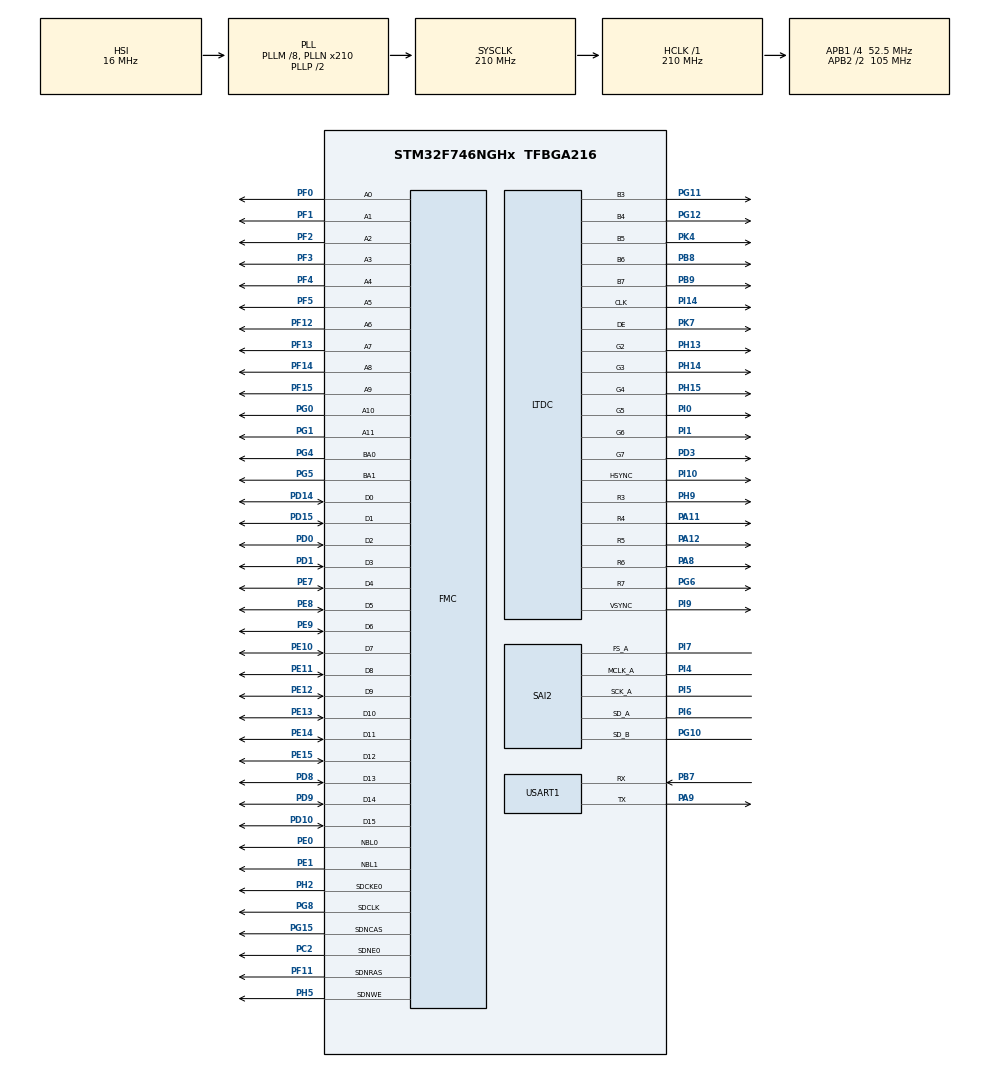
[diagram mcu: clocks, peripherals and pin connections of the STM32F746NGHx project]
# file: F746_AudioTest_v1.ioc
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Dma.Request0=SAI2_A
Dma.Request1=SAI2_B
Dma.SAI2_A.0.Direction=DMA_MEMORY_TO_PERIPH
Dma.SAI2_A.0.FIFOMode=DMA_FIFOMODE_DISABLE
Dma.SAI2_A.0.Instance=DMA2_Stream4
Dma.SAI2_A.0.MemDataAlignment=DMA_MDATAALIGN_HALFWORD
Dma.SAI2_A.0.MemInc=DMA_MINC_ENABLE
Dma.SAI2_A.0.Mode=DMA_CIRCULAR
Dma.SAI2_A.0.PeriphDataAlignment=DMA_PDATAALIGN_HALFWORD
Dma.SAI2_A.0.PeriphInc=DMA_PINC_DISABLE
Dma.SAI2_A.0.Priority=DMA_PRIORITY_HIGH
Dma.SAI2_B.1.Direction=DMA_PERIPH_TO_MEMORY
Dma.SAI2_B.1.FIFOMode=DMA_FIFOMODE_DISABLE
Dma.SAI2_B.1.Instance=DMA2_Stream6
Dma.SAI2_B.1.MemDataAlignment=DMA_MDATAALIGN_HALFWORD
Dma.SAI2_B.1.MemInc=DMA_MINC_ENABLE
Dma.SAI2_B.1.Mode=DMA_CIRCULAR
Dma.SAI2_B.1.PeriphDataAlignment=DMA_PDATAALIGN_HALFWORD
Dma.SAI2_B.1.PeriphInc=DMA_PINC_DISABLE
Dma.SAI2_B.1.Priority=DMA_PRIORITY_HIGH
Mcu.Family=STM32F7
Mcu.Name=STM32F746NGHx
Mcu.Package=TFBGA216
NVIC.DMA2D_IRQn=true\:0\:0\:false\:false\:true\:true\:true\:true
NVIC.DMA2_Stream4_IRQn=true\:0\:0\:false\:false\:true\:false\:true\:true
NVIC.DMA2_Stream6_IRQn=true\:0\:0\:false\:false\:true\:false\:true\:true
NVIC.LTDC_IRQn=true\:0\:0\:false\:false\:true\:true\:true\:true
NVIC.PriorityGroup=NVIC_PRIORITYGROUP_4
PA11.Mode=RGB565
PA11.Signal=LTDC_R4
PA12.Mode=RGB565
PA12.Signal=LTDC_R5
PA13.Mode=Serial_Wire
PA13.Signal=SYS_JTMS-SWDIO
PA14.Mode=Serial_Wire
PA14.Signal=SYS_JTCK-SWCLK
PA8.Mode=RGB565
PA8.Signal=LTDC_R6
PA9.Mode=Asynchronous
PA9.Signal=USART1_TX
PB7.Mode=Asynchronous
PB7.Signal=USART1_RX
PB8.Mode=RGB565
PB8.Signal=LTDC_B6
PB9.Mode=RGB565
PB9.Signal=LTDC_B7
PC14/OSC32_IN.Mode=LSE-External-Oscillator
PC14/OSC32_IN.Signal=RCC_OSC32_IN
PC15/OSC32_OUT.Mode=LSE-External-Oscillator
PC15/OSC32_OUT.Signal=RCC_OSC32_OUT
PC2.Mode=SdramChipSelect1_1
PC2.Signal=FMC_SDNE0
PD0.Signal=FMC_D2_DA2
PD1.Signal=FMC_D3_DA3
PD10.Signal=FMC_D15_DA15
PD14.Signal=FMC_D0_DA0
PD15.Signal=FMC_D1_DA1
PD3.Mode=RGB565
PD3.Signal=LTDC_G7
PD8.Signal=FMC_D13_DA13
PD9.Signal=FMC_D14_DA14
PE0.Signal=FMC_NBL0
PE1.Signal=FMC_NBL1
PE10.Signal=FMC_D7_DA7
PE11.Signal=FMC_D8_DA8
PE12.Signal=FMC_D9_DA9
PE13.Signal=FMC_D10_DA10
PE14.Signal=FMC_D11_DA11
PE15.Signal=FMC_D12_DA12
PE7.Signal=FMC_D4_DA4
PE8.Signal=FMC_D5_DA5
PE9.Signal=FMC_D6_DA6
PF0.Signal=FMC_A0
PF1.Signal=FMC_A1
PF11.Signal=FMC_SDNRAS
PF12.Signal=FMC_A6
PF13.Signal=FMC_A7
PF14.Signal=FMC_A8
PF15.Signal=FMC_A9
PF2.Signal=FMC_A2
PF3.Signal=FMC_A3
PF4.Signal=FMC_A4
PF5.Signal=FMC_A5
PG0.Signal=FMC_A10
PG1.Signal=FMC_A11
PG10.Mode=SAI_B_SyncSlave
PG10.Signal=SAI2_SD_B
PG11.Mode=RGB565
PG11.Signal=LTDC_B3
PG12.Mode=RGB565
PG12.Signal=LTDC_B4
PG15.Signal=FMC_SDNCAS
PG4.Signal=FMC_A14_BA0
PG5.Signal=FMC_A15_BA1
PG6.Mode=RGB565
PG6.Signal=LTDC_R7
PG8.Signal=FMC_SDCLK
PH0/OSC_IN.Mode=HSE-External-Oscillator
PH0/OSC_IN.Signal=RCC_OSC_IN
PH1/OSC_OUT.Mode=HSE-External-Oscillator
PH1/OSC_OUT.Signal=RCC_OSC_OUT
PH13.Mode=RGB565
PH13.Signal=LTDC_G2
PH14.Mode=RGB565
PH14.Signal=LTDC_G3
PH15.Mode=RGB565
PH15.Signal=LTDC_G4
PH2.Mode=SdramChipSelect1_1
PH2.Signal=FMC_SDCKE0
PH5.Signal=FMC_SDNWE
PH9.Mode=RGB565
PH9.Signal=LTDC_R3
PI0.Mode=RGB565
PI0.Signal=LTDC_G5
PI1.Mode=RGB565
PI1.Signal=LTDC_G6
PI10.Mode=RGB565
PI10.Signal=LTDC_HSYNC
PI14.Mode=RGB565
PI14.Signal=LTDC_CLK
PI4.Mode=SAI_A_MasterWithClock
PI4.Signal=SAI2_MCLK_A
PI5.Mode=SAI_A_MasterWithClock
PI5.Signal=SAI2_SCK_A
PI6.Mode=SAI_A_MasterWithClock
PI6.Signal=SAI2_SD_A
PI7.Mode=SAI_A_MasterWithClock
PI7.Signal=SAI2_FS_A
PI9.Mode=RGB565
PI9.Signal=LTDC_VSYNC
PK4.Mode=RGB565
PK4.Signal=LTDC_B5
PK7.Mode=RGB565
PK7.Signal=LTDC_DE
ProjectManager.HeapSize=0x200
ProjectManager.StackSize=0x400
ProjectManager.TargetToolchain=CMake
RCC.AHBFreq_Value=210000000
RCC.APB1CLKDivider=RCC_HCLK_DIV4
RCC.APB1Freq_Value=52500000
RCC.APB1TimFreq_Value=105000000
RCC.APB2CLKDivider=RCC_HCLK_DIV2
RCC.APB2Freq_Value=105000000
RCC.APB2TimFreq_Value=210000000
RCC.CortexFreq_Value=210000000
RCC.HCLKFreq_Value=210000000
RCC.HSE_VALUE=25000000
RCC.HSI_VALUE=16000000
RCC.PLLM=8
RCC.PLLN=210
RCC.PLLSAIN=50
RCC.PLLSourceVirtual=RCC_PLLSOURCE_HSI
RCC.SYSCLKFreq_VALUE=210000000
RCC.SYSCLKSource=RCC_SYSCLKSOURCE_PLLCLK
RCC.USBFreq_Value=210000000
RCC.VCOOutputFreq_Value=420000000
SAI2.ErrorAudioFreq-SAI_A_MasterWithClock=56.25 %
SAI2.Instance-SAI_A_MasterWithClock=SAI$Index_Block_A
SAI2.Instance-SAI_B_SyncSlave=SAI$Index_Block_B
SAI2.MClockEnable-SAI_A_MasterWithClock=SAI_MASTERCLOCK_ENABLE
SAI2.RealAudioFreq-SAI_A_MasterWithClock=300.0 KHz
SAI2.VirtualMode-SAI_A_MasterWithClock=VM_MASTER
SAI2.VirtualMode-SAI_B_SyncSlave=VM_SLAVE
SH.FMC_A0.0=FMC_A0,12b-sda1
SH.FMC_A1.0=FMC_A1,12b-sda1
SH.FMC_A10.0=FMC_A10,12b-sda1
SH.FMC_A11.0=FMC_A11,12b-sda1
SH.FMC_A14_BA0.0=FMC_BA0,FourSdramBanks1
SH.FMC_A15_BA1.0=FMC_BA1,FourSdramBanks1
SH.FMC_A2.0=FMC_A2,12b-sda1
SH.FMC_A3.0=FMC_A3,12b-sda1
SH.FMC_A4.0=FMC_A4,12b-sda1
SH.FMC_A5.0=FMC_A5,12b-sda1
SH.FMC_A6.0=FMC_A6,12b-sda1
SH.FMC_A7.0=FMC_A7,12b-sda1
SH.FMC_A8.0=FMC_A8,12b-sda1
SH.FMC_A9.0=FMC_A9,12b-sda1
SH.FMC_D0_DA0.0=FMC_D0,sd-16b-d1
SH.FMC_D10_DA10.0=FMC_D10,sd-16b-d1
SH.FMC_D11_DA11.0=FMC_D11,sd-16b-d1
SH.FMC_D12_DA12.0=FMC_D12,sd-16b-d1
SH.FMC_D13_DA13.0=FMC_D13,sd-16b-d1
SH.FMC_D14_DA14.0=FMC_D14,sd-16b-d1
SH.FMC_D15_DA15.0=FMC_D15,sd-16b-d1
SH.FMC_D1_DA1.0=FMC_D1,sd-16b-d1
SH.FMC_D2_DA2.0=FMC_D2,sd-16b-d1
SH.FMC_D3_DA3.0=FMC_D3,sd-16b-d1
SH.FMC_D4_DA4.0=FMC_D4,sd-16b-d1
SH.FMC_D5_DA5.0=FMC_D5,sd-16b-d1
SH.FMC_D6_DA6.0=FMC_D6,sd-16b-d1
SH.FMC_D7_DA7.0=FMC_D7,sd-16b-d1
SH.FMC_D8_DA8.0=FMC_D8,sd-16b-d1
SH.FMC_D9_DA9.0=FMC_D9,sd-16b-d1
SH.FMC_NBL0.0=FMC_NBL0,Sd2ByteEnable1
SH.FMC_NBL1.0=FMC_NBL1,Sd2ByteEnable1
SH.FMC_SDCLK.0=FMC_SDCLK,12b-sda1
SH.FMC_SDNCAS.0=FMC_SDNCAS,12b-sda1
SH.FMC_SDNRAS.0=FMC_SDNRAS,12b-sda1
SH.FMC_SDNWE.0=FMC_SDNWE,12b-sda1
USART1.VirtualMode-Asynchronous=VM_ASYNC
VP_DMA2D_VS_DMA2D.Mode=DMA2D_Activate
VP_TIM1_VS_ClockSourceINT.Mode=Internal
board=STM32F746G-DISCO

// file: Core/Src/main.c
/* USER CODE BEGIN Header */
/**
 ******************************************************************************
 * @file           : main.c
 * @brief          : Main program body
 ******************************************************************************
 * @attention
 *
 * Copyright (c) 2024 STMicroelectronics.
 * All rights reserved.
 *
 * This software is licensed under terms that can be found in the LICENSE file
 * in the root directory of this software component.
 * If no LICENSE file comes with this software, it is provided AS-IS.
 *
 ******************************************************************************
 */
/* USER CODE END Header */
#include "main.h"
#include "dma.h"
#include "dma2d.h"
#include "ltdc.h"
#include "sai.h"
#include "tim.h"
#include "usart.h"
#include "gpio.h"
#include "fmc.h"

/* USER CODE BEGIN Includes */
#include <stdio.h>
#include "stm32746g_discovery.h"
#include "stm32746g_discovery_audio.h"
#include "stm32746g_discovery_lcd.h"
#include "stm32746g_discovery_sdram.h"
#include "distortion.h"
#include "delay.h"
#include "wahwah.h"
/* USER CODE END Includes */

/* USER CODE BEGIN PTD */
typedef enum
{
  BUFFER_OFFSET_NONE = 0,
  BUFFER_OFFSET_HALF,
  BUFFER_OFFSET_FULL,
} BUFFER_StateTypeDef;
/* USER CODE END PTD */

/* USER CODE BEGIN PV */
extern SAI_HandleTypeDef haudio_out_sai;
extern SAI_HandleTypeDef haudio_in_sai;
static int16_t sampleBuffer[BUFFER_SIZE_SAMPLES];
static uint8_t saiDMATransmitBuffer[DMA_BUFFER_SIZE_BYTES];
static uint8_t saiDMAReceiveBuffer[DMA_BUFFER_SIZE_BYTES];
volatile uint32_t audio_rec_buffer_state;

// LCD Fonts
extern sFONT Font24;
extern sFONT Font20;
extern sFONT Font16;
extern sFONT Font12;
extern sFONT Font8;
/* USER CODE END PV */

void SystemClock_Config(void);
void PeriphCommonClock_Config(void);
/* USER CODE BEGIN PFP */
void PrintDMABuffer(uint8_t *buffer, size_t size);
void PrintSampleBuffer(int16_t *buffer, size_t size);
void BSP_Bringup(void);
static void AudioInit(void);
static void FillSquareWave(int16_t *buf, uint32_t num_samples);
static void ConvertSampleToDMA(int16_t *sampleBuffer, uint8_t *dmaBuffer, uint32_t num_samples);
static void ExtractSampleFromDMA(uint8_t *dmaBuffer, int16_t *sampleBuffer, uint32_t num_samples);
static void CopySampleBuffer(int16_t *dest, int16_t *orig, uint32_t num_samples);
static void CopyDMABuffer(uint8_t *dest, uint8_t *orig, uint32_t num_samples);
/* USER CODE END PFP */

/* USER CODE BEGIN 0 */
PUTCHAR_PROTOTYPE
{
  HAL_UART_Transmit(&huart1, (uint8_t *)&ch, 1, 0xFFFF);
  return ch;
}
/* USER CODE END 0 */

int main(void)
{

  /* MCU Configuration--------------------------------------------------------*/

  /* Reset of all peripherals, Initializes the Flash interface and the Systick. */
  HAL_Init();

  /* Configure the system clock */
  SystemClock_Config();

  /* Configure the peripherals common clocks */
  PeriphCommonClock_Config();

  /* Initialize all configured peripherals */
  MX_GPIO_Init();
  MX_DMA_Init();
  MX_SAI2_Init();
  MX_TIM1_Init();
  MX_USART1_UART_Init();
  MX_DMA2D_Init();
  MX_FMC_Init();
  MX_LTDC_Init();
  /* USER CODE BEGIN 2 */
  // BSP LCD Initialization
  BSP_LCD_Init();
  BSP_LCD_LayerDefaultInit(0, LCD_FB_START_ADDRESS);
  BSP_LCD_DisplayOn();
  // Layer 0
  BSP_LCD_SelectLayer(0);
  BSP_LCD_Clear(LCD_COLOR_BLACK);
  BSP_LCD_SetBackColor(LCD_COLOR_BLACK);
  BSP_LCD_SetTextColor(LCD_COLOR_WHITE);
  // Start
  BSP_LCD_SelectLayer(0);
  BSP_LCD_SetFont(&Font20);
  BSP_LCD_DisplayStringAt(0, 10, (uint8_t *)"Electric Guitar Effect Pedal", CENTER_MODE);

  // Audio Setup
  AudioInit();
  audio_rec_buffer_state = BUFFER_OFFSET_NONE;

  // Effect Setup
  WahWah_Init();
  /* USER CODE END 2 */

  /* Infinite loop */
  /* USER CODE BEGIN WHILE */
  while (1)
  {
    if (audio_rec_buffer_state != BUFFER_OFFSET_NONE)
    {
      if (audio_rec_buffer_state == BUFFER_OFFSET_HALF)
      {
        // PrintDMABuffer(&saiDMAReceiveBuffer[0], 20);
        // DistortionProcess(&saiDMAReceiveBuffer[0], 1, 600, DMA_BUFFER_SIZE_BYTES / 2);
        // DelayProcess(&saiDMAReceiveBuffer[0], 0.7, 5000, DMA_BUFFER_SIZE_BYTES / 2);
        WahWahProcess(&saiDMAReceiveBuffer[0], 250, 3, 0.3, DMA_BUFFER_SIZE_BYTES / 2);
        CopyDMABuffer(&saiDMATransmitBuffer[0], &saiDMAReceiveBuffer[0], DMA_BUFFER_SIZE_BYTES / 2);
        // ExtractSampleFromDMA(&saiDMAReceiveBuffer[0], &sampleBuffer[0], BUFFER_SIZE_SAMPLES / 2);
        // ConvertSampleToDMA(&sampleBuffer[0], &saiDMATransmitBuffer[0], BUFFER_SIZE_SAMPLES / 2);
      }
      else if (audio_rec_buffer_state == BUFFER_OFFSET_FULL)
      {
        // PrintDMABuffer(&saiDMAReceiveBuffer[DMA_BUFFER_SIZE_BYTES / 2], 20);
        // DistortionProcess(&saiDMAReceiveBuffer[DMA_BUFFER_SIZE_BYTES / 2], 1, 600, DMA_BUFFER_SIZE_BYTES / 2);
        // DelayProcess(&saiDMAReceiveBuffer[DMA_BUFFER_SIZE_BYTES / 2], 0.7, 5000, DMA_BUFFER_SIZE_BYTES / 2);
        WahWahProcess(&saiDMAReceiveBuffer[DMA_BUFFER_SIZE_BYTES / 2], 250, 3, 0.3, DMA_BUFFER_SIZE_BYTES / 2);
        CopyDMABuffer(&saiDMATransmitBuffer[DMA_BUFFER_SIZE_BYTES / 2], &saiDMAReceiveBuffer[DMA_BUFFER_SIZE_BYTES / 2], DMA_BUFFER_SIZE_BYTES / 2);
        // ExtractSampleFromDMA(&saiDMAReceiveBuffer[DMA_BUFFER_SIZE_BYTES / 2], &sampleBuffer[DMA_BUFFER_SIZE_BYTES / 2], BUFFER_SIZE_SAMPLES / 2);
        // ConvertSampleToDMA(&sampleBuffer[DMA_BUFFER_SIZE_BYTES / 2], &saiDMATransmitBuffer[DMA_BUFFER_SIZE_BYTES / 2], BUFFER_SIZE_SAMPLES / 2);
      }
      audio_rec_buffer_state = BUFFER_OFFSET_NONE;
    }
    /* USER CODE END WHILE */

  }
}

void SystemClock_Config(void)
{
  RCC_OscInitTypeDef RCC_OscInitStruct = {0};
  RCC_ClkInitTypeDef RCC_ClkInitStruct = {0};

  /** Configure LSE Drive Capability
   */
  HAL_PWR_EnableBkUpAccess();

  /** Configure the main internal regulator output voltage
   */
  __HAL_RCC_PWR_CLK_ENABLE();
  __HAL_PWR_VOLTAGESCALING_CONFIG(PWR_REGULATOR_VOLTAGE_SCALE1);

  /** Initializes the RCC Oscillators according to the specified parameters
   * in the RCC_OscInitTypeDef structure.
   */
  RCC_OscInitStruct.OscillatorType = RCC_OSCILLATORTYPE_HSI;
  RCC_OscInitStruct.HSIState = RCC_HSI_ON;
  RCC_OscInitStruct.HSICalibrationValue = RCC_HSICALIBRATION_DEFAULT;
  RCC_OscInitStruct.PLL.PLLState = RCC_PLL_ON;
  RCC_OscInitStruct.PLL.PLLSource = RCC_PLLSOURCE_HSI;
  RCC_OscInitStruct.PLL.PLLM = 8;
  RCC_OscInitStruct.PLL.PLLN = 210;
  RCC_OscInitStruct.PLL.PLLP = RCC_PLLP_DIV2;
  RCC_OscInitStruct.PLL.PLLQ = 2;
  if (HAL_RCC_OscConfig(&RCC_OscInitStruct) != HAL_OK)
  {
    Error_Handler();
  }

  /** Activate the Over-Drive mode
   */
  if (HAL_PWREx_EnableOverDrive() != HAL_OK)
  {
    Error_Handler();
  }

  /** Initializes the CPU, AHB and APB buses clocks
   */
  RCC_ClkInitStruct.ClockType = RCC_CLOCKTYPE_HCLK | RCC_CLOCKTYPE_SYSCLK | RCC_CLOCKTYPE_PCLK1 | RCC_CLOCKTYPE_PCLK2;
  RCC_ClkInitStruct.SYSCLKSource = RCC_SYSCLKSOURCE_PLLCLK;
  RCC_ClkInitStruct.AHBCLKDivider = RCC_SYSCLK_DIV1;
  RCC_ClkInitStruct.APB1CLKDivider = RCC_HCLK_DIV4;
  RCC_ClkInitStruct.APB2CLKDivider = RCC_HCLK_DIV2;

  if (HAL_RCC_ClockConfig(&RCC_ClkInitStruct, FLASH_LATENCY_6) != HAL_OK)
  {
    Error_Handler();
  }
}

void PeriphCommonClock_Config(void)
{
  RCC_PeriphCLKInitTypeDef PeriphClkInitStruct = {0};

  /** Initializes the peripherals clock
   */
  PeriphClkInitStruct.PeriphClockSelection = RCC_PERIPHCLK_LTDC | RCC_PERIPHCLK_SAI2;
  PeriphClkInitStruct.PLLSAI.PLLSAIN = 50;
  PeriphClkInitStruct.PLLSAI.PLLSAIR = 2;
  PeriphClkInitStruct.PLLSAI.PLLSAIQ = 2;
  PeriphClkInitStruct.PLLSAI.PLLSAIP = RCC_PLLSAIP_DIV2;
  PeriphClkInitStruct.PLLSAIDivQ = 1;
  PeriphClkInitStruct.PLLSAIDivR = RCC_PLLSAIDIVR_2;
  PeriphClkInitStruct.Sai2ClockSelection = RCC_SAI2CLKSOURCE_PLLSAI;
  if (HAL_RCCEx_PeriphCLKConfig(&PeriphClkInitStruct) != HAL_OK)
  {
    Error_Handler();
  }
}

/* USER CODE BEGIN 4 */
void PrintDMABuffer(uint8_t *buffer, size_t size)
{
  for (size_t i = 0; i < size; i++)
  {
    printf("%u ", buffer[i]);
  }
  printf("\n");
}

void PrintSampleBuffer(int16_t *buffer, size_t size)
{
  for (size_t i = 0; i < size; i++)
  {
    printf("%i ", buffer[i]);
  }
  printf("\n");
}

void BSP_Bringup(void)
{
  FillSquareWave(sampleBuffer, BUFFER_SIZE_SAMPLES);
  ConvertSampleToDMA(sampleBuffer, saiDMATransmitBuffer, BUFFER_SIZE_SAMPLES);
  BSP_AUDIO_OUT_Init(OUTPUT_DEVICE_HEADPHONE, VOLUME, AUDIO_FREQ);
  HAL_SAI_Transmit_DMA(&haudio_out_sai, saiDMATransmitBuffer, DMA_BUFFER_SIZE_MSIZE);

  while (1)
    ;
}

static void AudioInit(void)
{
  BSP_AUDIO_OUT_ClockConfig(&haudio_in_sai, AUDIO_FREQ, NULL);
  BSP_AUDIO_OUT_MspInit(&haudio_out_sai, NULL);
  SAIx_Out_Init(AUDIO_FREQ);
  BSP_AUDIO_IN_MspInit(&haudio_in_sai, NULL);
  SAIx_In_Init(SAI_MODESLAVE_RX, 0xF, AUDIO_FREQ);
  wm8994_Init(AUDIO_I2C_ADDRESS, INPUT_DEVICE_INPUT_LINE_1 | OUTPUT_DEVICE_HEADPHONE, VOLUME, AUDIO_FREQ);

  HAL_SAI_Transmit_DMA(&haudio_out_sai, saiDMATransmitBuffer, DMA_BUFFER_SIZE_MSIZE);
  HAL_SAI_Receive_DMA(&haudio_in_sai, saiDMAReceiveBuffer, DMA_BUFFER_SIZE_MSIZE);
}

static void FillSquareWave(int16_t *buf, uint32_t num_samples)
{
  // fill up a 100 Hz square wave
  // 48 kHz sample rate -> 480 samples in 100 Hz -> toggle every 240 samples
  int toggle_period = 240;
  int count = 0;
  int wave_state = 1;
  int magnitude = 30000;

  for (int i = 0; i < num_samples; i++)
  {
    buf[i] = magnitude * wave_state;
    count++;
    if (count >= toggle_period)
    {
      count = 0;
      wave_state = wave_state * (-1);
    }
  }
}

static void ConvertSampleToDMA(int16_t *sampleBuffer, uint8_t *dmaBuffer, uint32_t num_samples)
{
  for (uint32_t i = 0; i < num_samples; i++)
  {
    int16_t *ptr = (int16_t *)&dmaBuffer[i * 8];
    *ptr = sampleBuffer[i];
    *(ptr + 2) = sampleBuffer[i];
  }
}

static void ExtractSampleFromDMA(uint8_t *dmaBuffer, int16_t *sampleBuffer, uint32_t num_samples)
{
  for (uint32_t i = 0; i < num_samples; i++)
  {
    int16_t *ptr = (int16_t *)&dmaBuffer[i * 8];
    sampleBuffer[i] = *ptr;
  }
}

static void CopySampleBuffer(int16_t *dest, int16_t *orig, uint32_t num_samples)
{
  for (uint32_t i = 0; i < num_samples; i++)
  {
    dest[i] = orig[i];
  }
}

static void CopyDMABuffer(uint8_t *dest, uint8_t *orig, uint32_t num_samples)
{
  for (uint32_t i = 0; i < num_samples; i++)
  {
    dest[i] = orig[i];
  }
}

void BSP_AUDIO_IN_TransferComplete_CallBack(void)
{
  audio_rec_buffer_state = BUFFER_OFFSET_FULL;
}

void BSP_AUDIO_IN_HalfTransfer_CallBack(void)
{
  audio_rec_buffer_state = BUFFER_OFFSET_HALF;
}
/* USER CODE END 4 */

void Error_Handler(void)
{
  __disable_irq();
  while (1)
  {
  }
}
